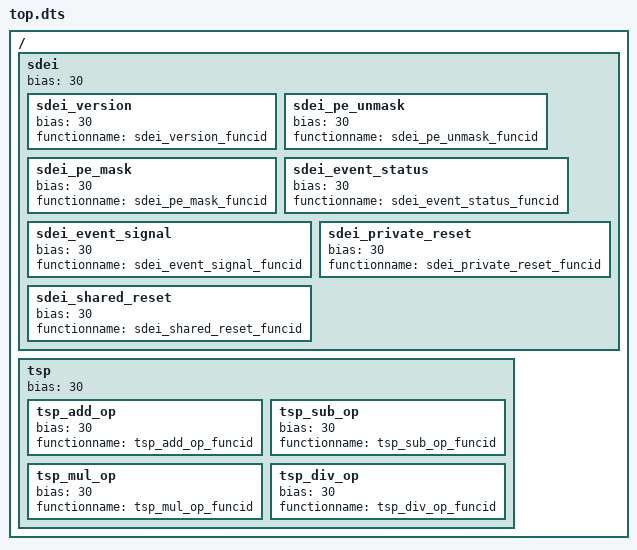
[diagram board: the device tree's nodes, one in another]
/*
 * Copyright (c) 2023, Arm Limited. All rights reserved.
 *
 * SPDX-License-Identifier: BSD-3-Clause
 */


/*
 * Top level device tree file to bias the SMC calls.  T
 * he biases are arbitrary and can be any value.
 * They are only significant when weighted against the
 * other biases.  30 was chosen arbitrarily.
 */

/dts-v1/;

/ {

	sdei {
		bias = <30>;
		sdei_version {
			bias = <30>;
			functionname = "sdei_version_funcid";
		};
		sdei_pe_unmask {
			bias = <30>;
			functionname = "sdei_pe_unmask_funcid";
		};
		sdei_pe_mask {
			bias = <30>;
			functionname = "sdei_pe_mask_funcid";
		};
		sdei_event_status {
			bias = <30>;
			functionname = "sdei_event_status_funcid";
		};
		sdei_event_signal {
			bias = <30>;
			functionname = "sdei_event_signal_funcid";
		};
		sdei_private_reset {
			bias = <30>;
			functionname = "sdei_private_reset_funcid";
		};
		sdei_shared_reset {
			bias = <30>;
			functionname = "sdei_shared_reset_funcid";
		};
	};
	tsp {
		bias = <30>;
		tsp_add_op {
			bias = <30>;
			functionname = "tsp_add_op_funcid";
		};
		tsp_sub_op {
			bias = <30>;
			functionname = "tsp_sub_op_funcid";
		};
		tsp_mul_op {
			bias = <30>;
			functionname = "tsp_mul_op_funcid";
		};
		tsp_div_op {
			bias = <30>;
			functionname = "tsp_div_op_funcid";
		};
	};
};
